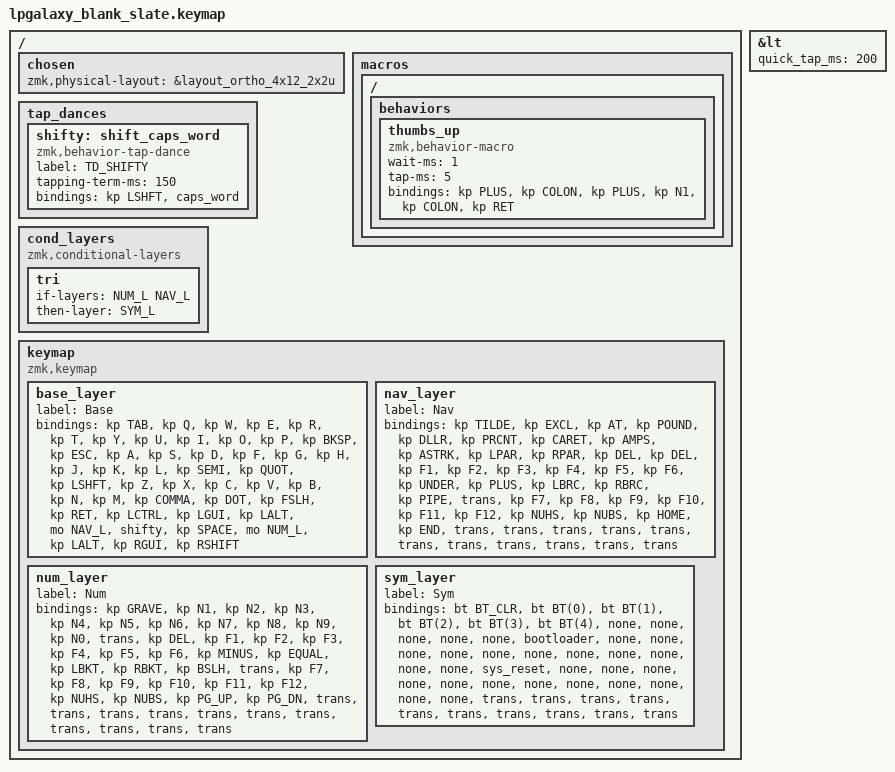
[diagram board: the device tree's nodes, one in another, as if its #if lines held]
/*
 * Copyright (c) 2022 Pete Johanson
 *
 * SPDX-License-Identifier: MIT
 */

#include <behaviors.dtsi>
#include <dt-bindings/zmk/keys.h>
#include <dt-bindings/zmk/bt.h>
#include <dt-bindings/zmk/outputs.h>

#define QWERTY_BASE 1

#define TBLE_ORTHO   1
// #define TBLE_MIT     1
// #define TBLE_DUAL_2U 1

#define NAV_L 1
#define NUM_L 2
#define SYM_L 3

// Using layer taps on thumbs, having quick tap as well helps w/ repeating space/backspace
&lt { quick_tap_ms = <200>; };

#define BT(n) BT_SEL n

/ {
    chosen {
       zmk,physical-layout =
#ifdef TBLE_DUAL_2U
                       &layout_ortho_4x12_2x2u;
#elif defined(TBLE_MIT)
                       &layout_ortho_4x12_1x2u;
#else
                       &layout_ortho_4x12_all1u;
#endif
    };

    macros {
      ZMK_MACRO(thumbs_up,
		wait-ms = <1>;
		tap-ms = <5>;
                bindings = <&kp PLUS &kp COLON &kp PLUS &kp N1 &kp COLON &kp RET>;
		)
    };
    
    tap_dances {
    	shifty: shift_caps_word {
		compatible = "zmk,behavior-tap-dance";
		label = "TD_SHIFTY";
		#binding-cells = <0>;
		tapping-term-ms = <150>;
		bindings = <&kp LSHFT>, <&caps_word>;
	};
    };

// Conditional layer only when we have less thumb keys
#ifdef TBLE_DUAL_2U
    cond_layers {
        compatible = "zmk,conditional-layers";
	tri {
	    if-layers = <NUM_L NAV_L>;
	    then-layer = <SYM_L>;
        };
    };
#endif

    keymap {
        compatible = "zmk,keymap";

        base_layer {
            label = "Base";
            bindings = <
#ifdef QWERTY_BASE
 &kp TAB    &kp Q      &kp W      &kp E       &kp R          &kp T          &kp Y            &kp U          &kp I       &kp O      &kp P         &kp BKSP
 &kp ESC    &kp A      &kp S      &kp D       &kp F          &kp G          &kp H            &kp J          &kp K       &kp L      &kp SEMI      &kp QUOT
 &kp LSHFT  &kp Z      &kp X      &kp C       &kp V          &kp B          &kp N            &kp M          &kp COMMA   &kp DOT    &kp FSLH      &kp RET
#else
 &kp ESC    &kp Q      &kp W      &kp F       &kp P          &kp B          &kp J            &kp L          &kp U       &kp Y      &kp QUOT      &kp BKSP
 &kp TAB    &kp A      &kp R      &kp S       &kp T          &kp G          &kp M            &kp N          &kp E       &kp I      &kp O         &kp QUOT
 &kp LSHFT  &kp Z      &kp X      &kp C       &kp D          &kp V          &kp K            &kp H          &kp COMMA   &kp DOT    &kp SEMI      &kp RET
#endif
#ifdef TBLE_DUAL_2U
 &kp LCTRL  &kp LGUI   &kp LALT   &mo NAV_L         &shifty                        &kp SPACE                &mo NUM_L   &kp LALT   &kp RGUI      &kp RSHIFT
#elif defined(TBLE_MIT)
 &mo SYM_L  &kp LCTRL   &kp LALT  &kp LGUI    &mo NAV_L          &kp SPACE                   &mo NUM_L      &kp LEFT    &kp DOWN   &kp UP        &kp RIGHT
#else
 &mo SYM_L  &kp LCTRL   &kp LALT  &kp LGUI    &mo NAV_L      &kp SPACE      &kp RET          &mo NUM_L      &kp LEFT    &kp DOWN     &kp UP      &kp RIGHT
#endif
            >;
        };

        nav_layer {
            label = "Nav";
            bindings = <
&kp TILDE  &kp EXCL   &kp AT     &kp POUND   &kp DLLR        &kp PRCNT    &kp CARET  &kp AMPS       &kp ASTRK   &kp LPAR   &kp RPAR   &kp DEL
&kp DEL    &kp F1     &kp F2     &kp F3      &kp F4          &kp F5       &kp F6     &kp UNDER      &kp PLUS    &kp LBRC   &kp RBRC   &kp PIPE
&trans      &kp F7     &kp F8     &kp F9      &kp F10         &kp F11      &kp F12    &kp NUHS       &kp NUBS    &kp HOME   &kp END    &trans
#ifdef TBLE_DUAL_2U
&trans  &trans        &trans     &trans              &trans                    &trans       &trans         &trans &trans &trans
#elif defined(TBLE_MIT)
&trans  &trans        &trans     &trans      &trans                &trans             &trans      &kp K_NEXT   &kp K_VOL_DN &kp K_VOL_UP &kp K_PP
#else
&trans  &trans        &trans     &trans      &trans          &trans       &trans    &trans  &kp K_NEXT   &kp K_VOL_DN &kp K_VOL_UP &kp K_PP
#endif
            >;
        };

        num_layer {
            label = "Num";
            bindings = <
&kp GRAVE  &kp N1     &kp N2     &kp N3      &kp N4          &kp N5       &kp N6        &kp N7     &kp N8      &kp N9       &kp N0     &trans
&kp DEL    &kp F1     &kp F2     &kp F3      &kp F4          &kp F5       &kp F6        &kp MINUS  &kp EQUAL   &kp LBKT     &kp RBKT   &kp BSLH
&trans     &kp F7     &kp F8     &kp F9      &kp F10         &kp F11      &kp F12	&kp NUHS   &kp NUBS    &kp PG_UP    &kp PG_DN  &trans
#ifdef TBLE_DUAL_2U
&trans  &trans       &trans     &trans              &trans                 &trans            &trans         &trans &trans &trans
#elif defined(TBLE_MIT)
&trans  &trans       &trans     &trans      &trans           &none            &trans        &kp K_NEXT      &kp K_VOL_DN &kp K_VOL_UP &kp K_PP
#else
&trans  &trans       &trans     &trans      &trans    &trans         &trans     &trans        &kp K_NEXT   &kp K_VOL_DN &kp K_VOL_UP &kp K_PP
#endif
            >;
        };

        sym_layer {
            label = "Sym";
            bindings = <
&bt BT_CLR &bt BT(0)  &bt BT(1)  &bt BT(2)   &bt BT(3)    &bt BT(4)    &none	  &none	    &none        &none        &none      &bootloader
&none	   &none      &none      &none       &none        &none        &none      &none     &none        &none        &none      &sys_reset
&none	   &none      &none      &none       &none        &none        &none      &none     &none        &none        &none      &none
#ifdef TBLE_DUAL_2U
&trans &trans        &trans     &trans                &trans                    &trans       &trans         &trans &trans &trans
#elif defined(TBLE_MIT)
&trans &trans        &trans     &trans        &trans                &trans             &trans      &trans   &trans &trans &soft_off
#else
&trans &trans        &trans     &trans        &trans          &trans       &trans    &trans  &trans         &trans &trans &soft_off
#endif
            >;
        };


    };
};

